# ATtiny412 device description
Architecture: AVR8X; Family: AVR TINY
Programming and debug interfaces: UPDI
Registers are 8-bit, read-write, no defined reset value unless marked. A register's access mark holds for its fields unless they carry their own. Offsets are from the block's base; lines under a group give offsets from that group; [hi:lo] are bit positions; {n}, {i} and the like mark numbered series; 'fields as' and 'values as' point back to an identical list; <NAME> marks a mode.

## Ordering variants
ATtiny412-SSFR: SOIC8, up to 20 MHz, -40 to 125 C, 1.8 to 5.5 V
ATtiny412-SSNR: SOIC8, up to 20 MHz, -40 to 105 C, 1.8 to 5.5 V

## Memory
data space: start 0x0000 size 0x9000, little endian
  0x00001400 EEPROM size 0x0080 eeprom, rw, page 0x20
  0x00001280 FUSES size 0xA fuses, rw, page 0x20
  0x3f00 INTERNAL_SRAM size 0x0100 ram, rw
  0x00000000 IO size 0x1100 io, rw
  0x0000128A LOCKBITS size 0x1 lockbits, rw, page 0x20
  0x00008000 MAPPED_PROGMEM size 0x1000 other, ro, page 0x40
  0x00001103 PROD_SIGNATURES size 0x3D signatures, ro, page 0x40
  0x00001100 SIGNATURES size 0x3 signatures, ro, page 0x40
  0x00001300 USER_SIGNATURES size 0x20 user_signatures, rw, page 0x20
prog space: start 0x0000 size 0x1000, little endian
  0x00000000 PROGMEM size 0x1000 flash, rw, executable, page 0x40

## Peripheral instances (address, pins/pin function, parameters)
AC0 at 0x0670 (AC)
  pins: N0 PA6; OUT PA3; P0 PA7
ADC0 at 0x0600 (ADC)
  pins: AIN0 PA0/AIN0; AIN1 PA1/AIN0; AIN2 PA2/AIN0; AIN3 PA3/AIN0; AIN6 PA6/AIN0; AIN7 PA7/AIN0
BOD at 0x0080
CCL at 0x01C0
  pins: LUT0_IN0 PA0; LUT0_IN1 PA1; LUT0_IN2 PA2; LUT1_OUT0 PA6
CLKCTRL at 0x0060
  pins: CLKI PA3
CPU at 0x0030
  pins: BREAK PA1/OTHER
CPUINT at 0x0110
CRCSCAN at 0x0120
DAC0 at 0x0680 (DAC)
  pins: OUT0 PA6
EVSYS at 0x0180
  pins: EVAPA0 PA0/EVAINCH0; EVAPA1 PA1/EVAINCH0; EVAPA2 PA2/EVAINCH0; EVAPA3 PA3/EVAINCH0; EVAPA6 PA6/EVAINCH0; EVAPA7 PA7/EVAINCH0; EVOUT0 PA2; EVSPA0 PA0/EVSINCH0; EVSPA1 PA1/EVSINCH0; EVSPA2 PA2/EVSINCH0; EVSPA3 PA3/EVSINCH0; EVSPA6 PA6/EVSINCH0; EVSPA7 PA7/EVSINCH0
  pin routing set by: EVSYS.ASYNCCH0.ASYNCCH0, PORTMUX.CTRLA.EVOUT0, EVSYS.SYNCCH0.SYNCCH0
FUSE at 0x1280
GPIO at 0x001C
LOCKBIT at 0x128A
NVMCTRL at 0x1000
PORTA at 0x0400 (PORT)
  pins: PIN0 PA0/IOPORT; PIN1 PA1/IOPORT; PIN2 PA2/IOPORT; PIN3 PA3/IOPORT; PIN6 PA6/IOPORT; PIN7 PA7/IOPORT
PORTMUX at 0x0200
RSTCTRL at 0x0040
  pins: RESET PA0/OTHER
RTC at 0x0140
SIGROW at 0x1100
SLPCTRL at 0x0050
SPI0 at 0x0820 (SPI)
  pins: MISO PA7/SPI0_ALT or PA2; MOSI PA6/SPI0_ALT or PA1; SCK PA3; SS PA0
  pin routing set by: PORTMUX.CTRLB.SPI0
SYSCFG at 0x0F00
  pins: UPDI PA0/OTHER
TCA0 at 0x0A00 (TCA)
  pins: WO0 PA7/TCA0_ALT or PA3; WO1 PA1; WO2 PA2; WO3 PA3
  pin routing set by: PORTMUX.CTRLC.TCA00, PORTMUX.CTRLC.TCA01, PORTMUX.CTRLC.TCA02, PORTMUX.CTRLC.TCA03
TCB0 at 0x0A40 (TCB)
  pins: WO PA6
TCD0 at 0x0A80 (TCD)
  pins: WOA PA6; WOB PA7
TWI0 at 0x0810 (TWI)
  pins: SCL PA2; SDA PA1
USART0 at 0x0800 (USART)
  pins: RXD PA2/USART0_ALT or PA7; TXD PA1/USART0_ALT or PA6; XCK PA3; XDIR PA0
  pin routing set by: PORTMUX.CTRLB.USART0
USERROW at 0x1300
VPORTA at 0x0000 (VPORT)
VPORTB at 0x0004 (VPORT)
VPORTC at 0x0008 (VPORT)
VREF at 0x00A0
WDT at 0x0100

## Interrupts
1 NMI (CRCSCAN)
2 VLM (BOD)
3 PORT (PORTA)
6 CNT (RTC)
7 PIT (RTC)
8 LUNF (TCA0)
8 OVF (TCA0)
9 HUNF (TCA0)
10 LCMP0 (TCA0)
10 CMP0 (TCA0)
11 CMP1 (TCA0)
11 LCMP1 (TCA0)
12 CMP2 (TCA0)
12 LCMP2 (TCA0)
13 INT (TCB0)
14 OVF (TCD0)
15 TRIG (TCD0)
16 AC (AC0)
17 RESRDY (ADC0)
18 WCOMP (ADC0)
19 TWIS (TWI0)
20 TWIM (TWI0)
21 INT (SPI0)
22 RXC (USART0)
23 DRE (USART0)
24 TXC (USART0)
25 EE (NVMCTRL)

## Properties
OCD_FEATURES: BREAK_PIN=PA1
SIGNATURES: SIGNATURE0=0x1E, SIGNATURE1=0x92, SIGNATURE2=0x23

## Pinouts (pin number, pad)
SOIC8: 1 VDD, 2 PA6, 3 PA7, 4 PA2, 5 PA1, 6 PA0, 7 PA3, 8 GND

## AC — Analog Comparator
Instances: AC0 0x0670
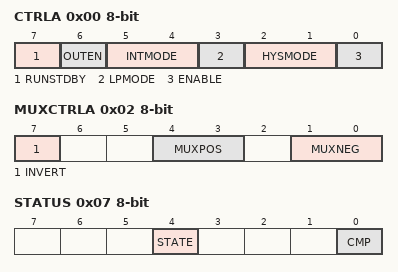
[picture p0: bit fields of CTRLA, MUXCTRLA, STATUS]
0x00 CTRLA — Control A
  [7] RUNSTDBY — Run in Standby Mode
  [6] OUTEN — Output Buffer Enable
  [5:4] INTMODE — Interrupt Mode
    0=BOTHEDGE (Any Edge); 2=NEGEDGE (Negative Edge); 3=POSEDGE (Positive Edge)
  [3] LPMODE — Low Power Mode
    0=DIS (Low power mode disabled); 1=EN (Low power mode enabled)
  [2:1] HYSMODE — Hysteresis Mode
    0=OFF (No hysteresis); 1=10mV hysteresis; 2=25mV hysteresis; 3=50mV hysteresis
  [0] ENABLE
0x02 MUXCTRLA — Mux Control A
  [7] INVERT — Invert AC Output
  [4:3] MUXPOS — Positive Input MUX Selection
    0=PIN0 (Positive Pin 0); 1=PIN1 (Positive Pin 1)
  [1:0] MUXNEG — Negative Input MUX Selection
    0=PIN0 (Negative Pin 0); 1=PIN1 (Negative Pin 1); 2=VREF (Voltage Reference); 3=DAC (DAC output)
0x06 INTCTRL — Interrupt Control
  [0] CMP — Analog Comparator 0 Interrupt Enable
0x07 STATUS
  [4] STATE ro — Analog Comparator State
  [0] CMP — Analog Comparator Interrupt Flag
